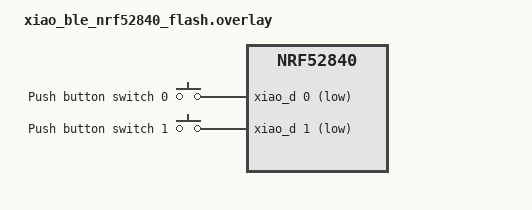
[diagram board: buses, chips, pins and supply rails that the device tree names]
/ {
    buttons {
		compatible = "gpio-keys";

		button0: button_0 {
			gpios = <&xiao_d 0 (GPIO_PULL_UP | GPIO_ACTIVE_LOW)>;
			label = "Push button switch 0";
			zephyr,code = <INPUT_KEY_0>;
		};

		button1: button_1 {
			gpios = <&xiao_d 1 (GPIO_PULL_UP | GPIO_ACTIVE_LOW)>;
			label = "Push button switch 1";
			zephyr,code = <INPUT_KEY_1>;
		};
	};
};
